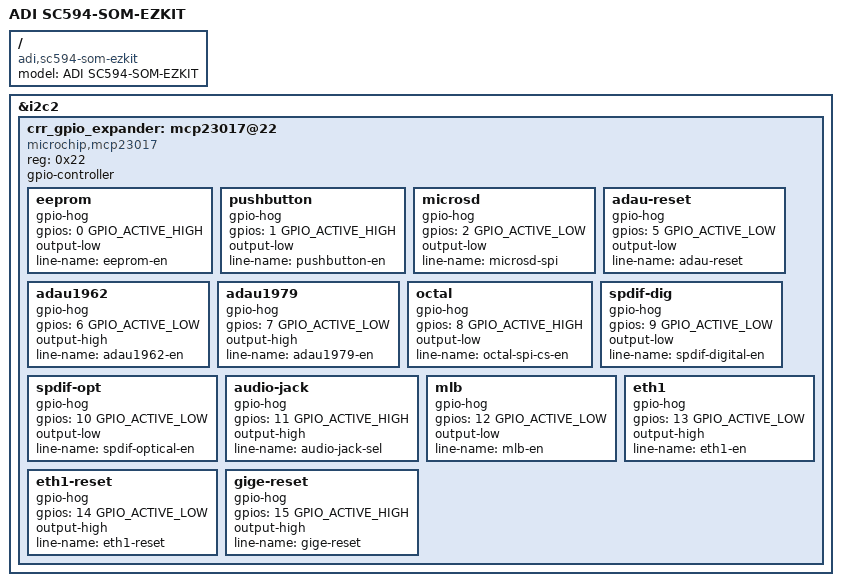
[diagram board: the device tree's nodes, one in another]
// SPDX-License-Identifier: GPL-2.0-or-later
/*
 * (C) Copyright 2024 - Analog Devices, Inc.
 */

/dts-v1/;

#include "sc594-som.dtsi"

/ {
	model = "ADI SC594-SOM-EZKIT";
	compatible = "adi,sc594-som-ezkit", "adi,sc59x";
};

&i2c2 {
	crr_gpio_expander: mcp23017@22 {
		compatible = "microchip,mcp23017";
		reg = <0x22>;
		gpio-controller;
		#gpio-cells = <2>;
		bootph-pre-ram;

		eeprom {
			gpio-hog;
			gpios = <0 GPIO_ACTIVE_HIGH>;
			output-low;
			line-name = "eeprom-en";
			bootph-pre-ram;
		};

		pushbutton {
			gpio-hog;
			gpios = <1 GPIO_ACTIVE_HIGH>;
			output-low;
			line-name = "pushbutton-en";
			bootph-pre-ram;
		};

		microsd {
			gpio-hog;
			gpios = <2 GPIO_ACTIVE_LOW>;
			output-low;
			line-name = "microsd-spi";
			bootph-pre-ram;
		};

		adau-reset {
			gpio-hog;
			gpios = <5 GPIO_ACTIVE_LOW>;
			output-low;
			line-name = "adau-reset";
			bootph-pre-ram;
		};

		adau1962 {
			gpio-hog;
			gpios = <6 GPIO_ACTIVE_LOW>;
			output-high;
			line-name = "adau1962-en";
			bootph-pre-ram;
		};

		adau1979 {
			gpio-hog;
			gpios = <7 GPIO_ACTIVE_LOW>;
			output-high;
			line-name = "adau1979-en";
			bootph-pre-ram;
		};

		octal {
			gpio-hog;
			gpios = <8 GPIO_ACTIVE_HIGH>;
			output-low;
			line-name = "octal-spi-cs-en";
			bootph-pre-ram;
		};

		spdif-dig {
			gpio-hog;
			gpios = <9 GPIO_ACTIVE_LOW>;
			output-low;
			line-name = "spdif-digital-en";
			bootph-pre-ram;
		};

		spdif-opt {
			gpio-hog;
			gpios = <10 GPIO_ACTIVE_LOW>;
			output-low;
			line-name = "spdif-optical-en";
			bootph-pre-ram;
		};

		audio-jack {
			gpio-hog;
			gpios = <11 GPIO_ACTIVE_HIGH>;
			output-high;
			line-name = "audio-jack-sel";
			bootph-pre-ram;
		};

		mlb {
			gpio-hog;
			gpios = <12 GPIO_ACTIVE_LOW>;
			output-low;
			line-name = "mlb-en";
			bootph-pre-ram;
		};

		eth1 {
			gpio-hog;
			gpios = <13 GPIO_ACTIVE_LOW>;
			output-high;
			line-name = "eth1-en";
			bootph-pre-ram;
		};

		eth1-reset {
			gpio-hog;
			gpios = <14 GPIO_ACTIVE_LOW>;
			/*
			 * USB0 lines are shared with Eth1 so  Eth PHY must be held in reset
			 * when using the USB
			 */
			output-high;
			line-name = "eth1-reset";
			bootph-pre-ram;
		};

		gige-reset {
			gpio-hog;
			gpios = <15 GPIO_ACTIVE_HIGH>;
			output-high;
			line-name = "gige-reset";
			bootph-pre-ram;
		};
	};
};
